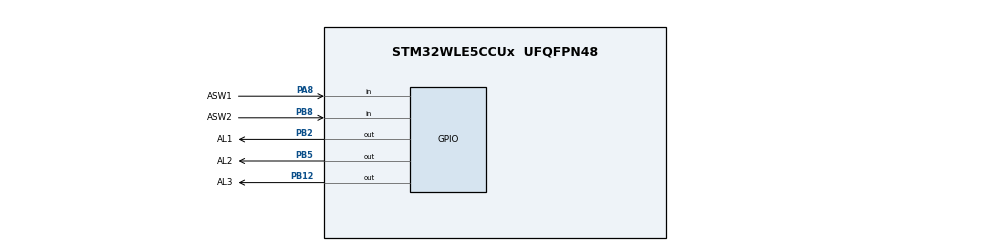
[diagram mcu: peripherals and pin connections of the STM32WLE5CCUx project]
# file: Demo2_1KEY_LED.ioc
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Mcu.Family=STM32WL
Mcu.Name=STM32WLE5CCUx
Mcu.Package=UFQFPN48
NVIC.PriorityGroup=NVIC_PRIORITYGROUP_4
PA13.Mode=Serial_Wire
PA13.Signal=DEBUG_JTMS-SWDIO
PA14.Mode=Serial_Wire
PA14.Signal=DEBUG_JTCK-SWCLK
PA8.GPIO_Label=ASW1
PA8.Signal=GPIO_Input
PB12.GPIO_Label=AL3
PB12.PinState=GPIO_PIN_SET
PB12.Signal=GPIO_Output
PB2.GPIO_Label=AL1
PB2.PinState=GPIO_PIN_SET
PB2.Signal=GPIO_Output
PB5.GPIO_Label=AL2
PB5.PinState=GPIO_PIN_SET
PB5.Signal=GPIO_Output
PB8.GPIO_Label=ASW2
PB8.Signal=GPIO_Input
ProjectManager.HeapSize=0x200
ProjectManager.StackSize=0x400
ProjectManager.TargetToolchain=MDK-ARM V5.37
RCC.AHBFreq_Value=48000000
RCC.APB1Freq_Value=48000000
RCC.APB1TimFreq_Value=48000000
RCC.APB2Freq_Value=48000000
RCC.APB2TimFreq_Value=48000000
RCC.APB3Freq_Value=48000000
RCC.CortexFreq_Value=48000000
RCC.HCLKFreq_Value=48000000
RCC.HSE_VALUE=8000000
RCC.HSI_VALUE=16000000
RCC.LSE_VALUE=32768
RCC.MSIClockRange=RCC_MSIRANGE_11
RCC.SYSCLKFreq_VALUE=48000000
RCC.VCOOutputFreq_Value=384000000
board=custom

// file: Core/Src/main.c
/* USER CODE BEGIN Header */
/**
  ******************************************************************************
  * @file           : main.c
  * @brief          : Main program body
  ******************************************************************************
  * @attention
  *
  * Copyright (c) 2024 STMicroelectronics.
  * All rights reserved.
  *
  * This software is licensed under terms that can be found in the LICENSE file
  * in the root directory of this software component.
  * If no LICENSE file comes with this software, it is provided AS-IS.
  *
  ******************************************************************************
  */
/* USER CODE END Header */
#include "main.h"
#include "gpio.h"

void SystemClock_Config(void);

int main(void)
{

    /* MCU Configuration--------------------------------------------------------*/

    /* Reset of all peripherals, Initializes the Flash interface and the Systick. */
    HAL_Init();

    /* Configure the system clock */
    SystemClock_Config();

    /* Initialize all configured peripherals */
    MX_GPIO_Init();

    /* Infinite loop */
    /* USER CODE BEGIN WHILE */
    while (1)
    {
        if(HAL_GPIO_ReadPin(ASW1_GPIO_Port, ASW1_Pin) == GPIO_PIN_RESET)          //ASW1按键被按下
        {
            HAL_GPIO_TogglePin(AL1_GPIO_Port, AL1_Pin);                           //翻转AL1指示灯状态
            HAL_Delay(200);                                                       //消抖
            while(HAL_GPIO_ReadPin(ASW1_GPIO_Port, ASW1_Pin) == GPIO_PIN_RESET);  //松手检测
        }
        if(HAL_GPIO_ReadPin(ASW2_GPIO_Port, ASW2_Pin) == GPIO_PIN_RESET)          //ASW2按键被按下
        {
            HAL_GPIO_TogglePin(AL2_GPIO_Port, AL2_Pin);                           //翻转AL2指示灯状态
            HAL_Delay(200);                                                       //消抖
            while(HAL_GPIO_ReadPin(ASW2_GPIO_Port, ASW2_Pin) == GPIO_PIN_RESET);  //松手检测
        }
        /* USER CODE END WHILE */

    }
}

void SystemClock_Config(void)
{
    RCC_OscInitTypeDef RCC_OscInitStruct = {0};
    RCC_ClkInitTypeDef RCC_ClkInitStruct = {0};

    /** Configure the main internal regulator output voltage
    */
    __HAL_PWR_VOLTAGESCALING_CONFIG(PWR_REGULATOR_VOLTAGE_SCALE1);

    /** Initializes the CPU, AHB and APB buses clocks
    */
    RCC_OscInitStruct.OscillatorType = RCC_OSCILLATORTYPE_MSI;
    RCC_OscInitStruct.MSIState = RCC_MSI_ON;
    RCC_OscInitStruct.MSICalibrationValue = RCC_MSICALIBRATION_DEFAULT;
    RCC_OscInitStruct.MSIClockRange = RCC_MSIRANGE_11;
    RCC_OscInitStruct.PLL.PLLState = RCC_PLL_NONE;
    if (HAL_RCC_OscConfig(&RCC_OscInitStruct) != HAL_OK)
    {
        Error_Handler();
    }

    /** Configure the SYSCLKSource, HCLK, PCLK1 and PCLK2 clocks dividers
    */
    RCC_ClkInitStruct.ClockType = RCC_CLOCKTYPE_HCLK3 | RCC_CLOCKTYPE_HCLK
                                  | RCC_CLOCKTYPE_SYSCLK | RCC_CLOCKTYPE_PCLK1
                                  | RCC_CLOCKTYPE_PCLK2;
    RCC_ClkInitStruct.SYSCLKSource = RCC_SYSCLKSOURCE_MSI;
    RCC_ClkInitStruct.AHBCLKDivider = RCC_SYSCLK_DIV1;
    RCC_ClkInitStruct.APB1CLKDivider = RCC_HCLK_DIV1;
    RCC_ClkInitStruct.APB2CLKDivider = RCC_HCLK_DIV1;
    RCC_ClkInitStruct.AHBCLK3Divider = RCC_SYSCLK_DIV1;

    if (HAL_RCC_ClockConfig(&RCC_ClkInitStruct, FLASH_LATENCY_2) != HAL_OK)
    {
        Error_Handler();
    }
}

void Error_Handler(void)
{
    __disable_irq();
    while (1)
    {
    }
}
